# SPC1169 register map
File version: 2022071043481212
CPU: cm4 r1p0, little endian, no MPU, FPU, 4 interrupt priority bits
Registers are 32-bit, read-write, reset 0x0 unless marked. A register's access mark holds for its fields unless they carry their own. Offsets are from the block's base; [hi:lo] are bit positions; {n}, {i} and the like mark numbered series; 'fields as' and 'values as' point back to an identical list.

## GPIO
Base 0x40001200
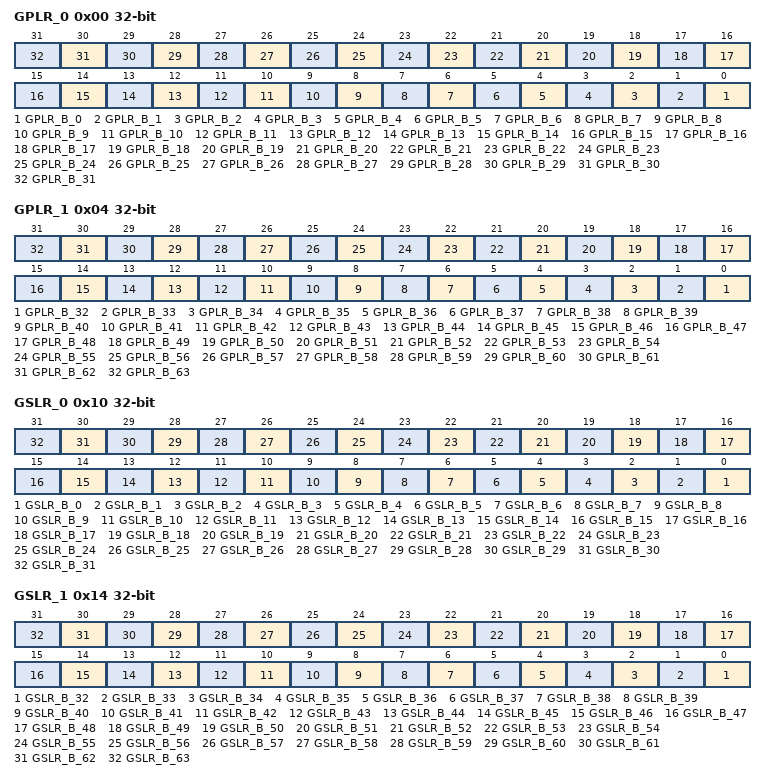
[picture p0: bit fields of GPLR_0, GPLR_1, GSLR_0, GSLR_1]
0x00 GPLR_0 — GPIO Pin Level Register [0]
  [n] GPLR_B_{n} (n=0..31)
0x04 GPLR_1 — GPIO Pin Level Register [1]
  [n-32] GPLR_B_{n} (n=32..63)
0x10 GSLR_0 — GPIO Pin Output Set Register [0]
  [n] GSLR_B_{n} (n=0..31)
0x14 GSLR_1 — GPIO Pin Output Set Register [1]
  [n-32] GSLR_B_{n} (n=32..63)
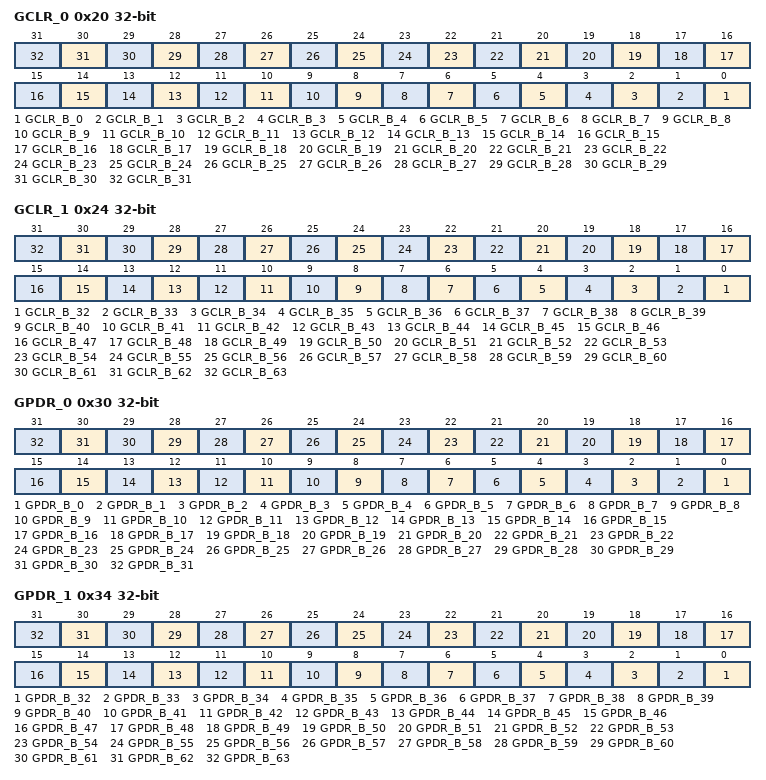
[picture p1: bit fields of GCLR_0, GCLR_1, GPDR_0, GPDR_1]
0x20 GCLR_0 — GPIO Pin Output Clear Register [0]
  [n] GCLR_B_{n} (n=0..31)
0x24 GCLR_1 — GPIO Pin Output Clear Register [1]
  [n-32] GCLR_B_{n} (n=32..63)
0x30 GPDR_0 — GPIO Pin Direction Register [0]
  [n] GPDR_B_{n} (n=0..31)
0x34 GPDR_1 — GPIO Pin Direction Register [1]
  [n-32] GPDR_B_{n} (n=32..63)
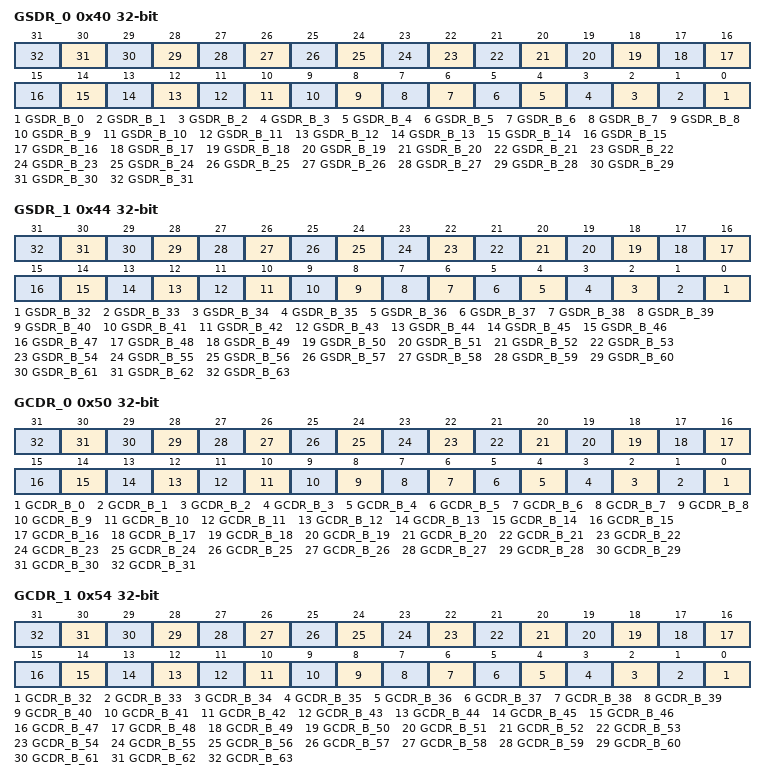
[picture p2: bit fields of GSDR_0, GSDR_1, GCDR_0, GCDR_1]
0x40 GSDR_0 — GPIO Pin Bitwise Set Direction Register [0]
  [n] GSDR_B_{n} (n=0..31)
0x44 GSDR_1 — GPIO Pin Bitwise Set Direction Register [1]
  [n-32] GSDR_B_{n} (n=32..63)
0x50 GCDR_0 — GPIO Pin Bitwise Clear Direction Register [0]
  [n] GCDR_B_{n} (n=0..31)
0x54 GCDR_1 — GPIO Pin Bitwise Clear Direction Register [1]
  [n-32] GCDR_B_{n} (n=32..63)
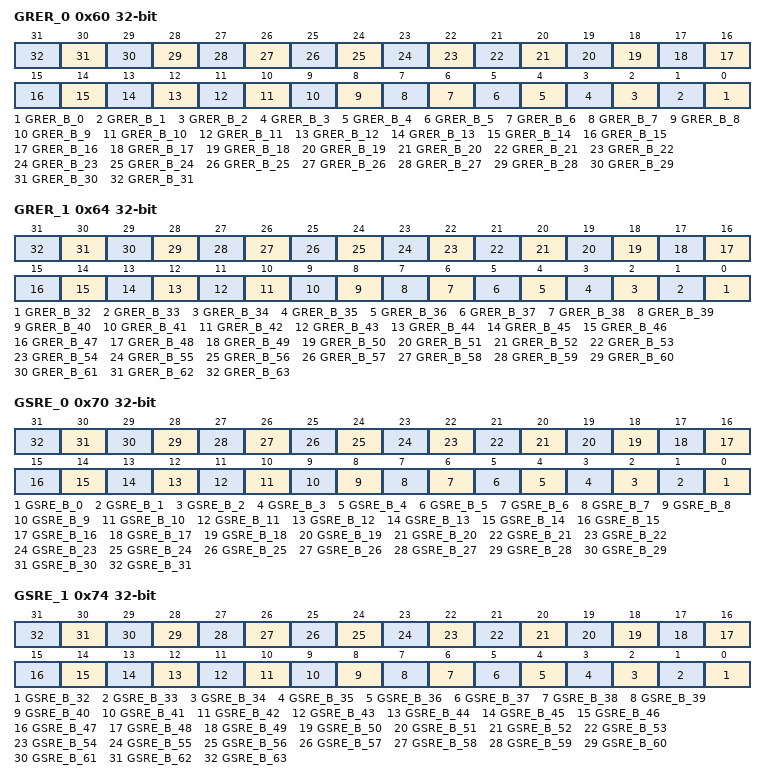
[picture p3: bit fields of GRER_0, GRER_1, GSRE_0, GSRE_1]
0x60 GRER_0 — GPIO Pin Rising Edge Detect Enable Register [0]
  [n] GRER_B_{n} (n=0..31)
0x64 GRER_1 — GPIO Pin Rising Edge Detect Enable Register [1]
  [n-32] GRER_B_{n} (n=32..63)
0x70 GSRE_0 — GPIO Pin Bitwise Set Rising Edge Detect Enable Register [0]
  [n] GSRE_B_{n} (n=0..31)
0x74 GSRE_1 — GPIO Pin Bitwise Set Rising Edge Detect Enable Register [1]
  [n-32] GSRE_B_{n} (n=32..63)
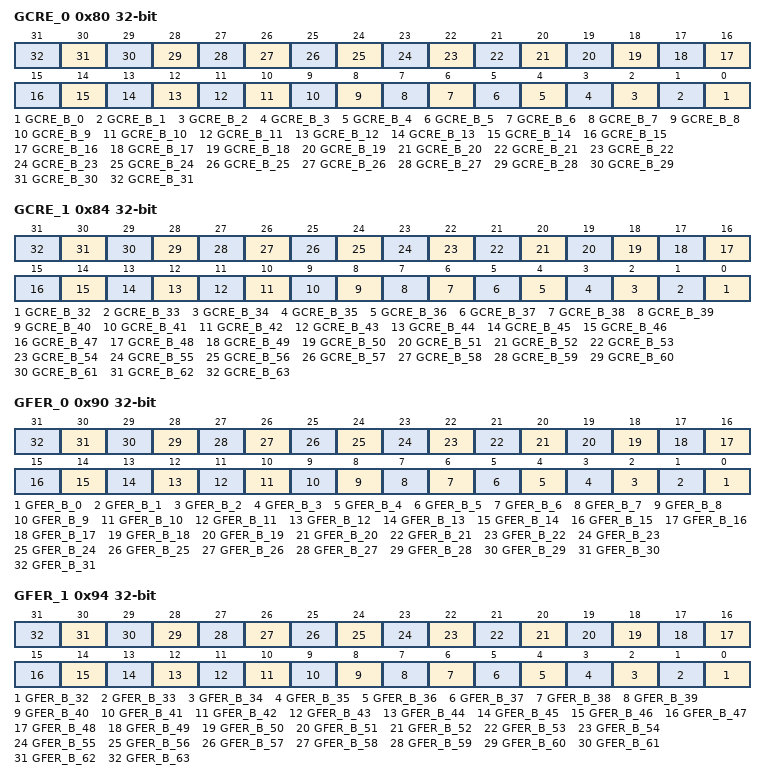
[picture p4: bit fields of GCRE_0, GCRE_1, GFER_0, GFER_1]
0x80 GCRE_0 — GPIO Pin Bitwise Clear Rising Edge Detect Enable Register [0]
  [n] GCRE_B_{n} (n=0..31)
0x84 GCRE_1 — GPIO Pin Bitwise Clear Rising Edge Detect Enable Register [1]
  [n-32] GCRE_B_{n} (n=32..63)
0x90 GFER_0 — GPIO Pin Falling Edge Detect Enable Register [0]
  [n] GFER_B_{n} (n=0..31)
0x94 GFER_1 — GPIO Pin Falling Edge Detect Enable Register [1]
  [n-32] GFER_B_{n} (n=32..63)
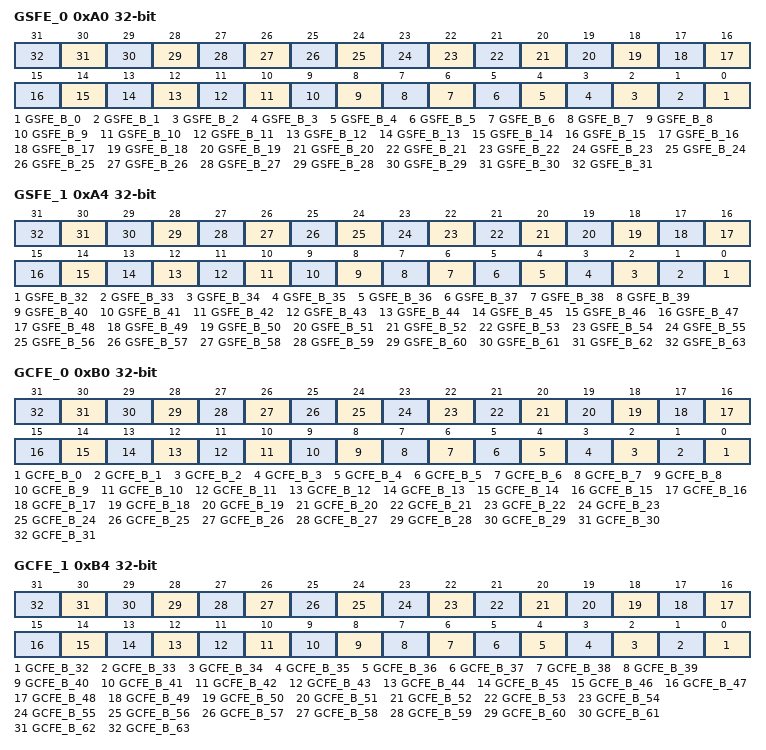
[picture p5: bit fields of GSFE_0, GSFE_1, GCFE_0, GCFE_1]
0xA0 GSFE_0 — GPIO Pin Bitwise Set Falling Edge Detect Enable Register [0]
  [n] GSFE_B_{n} (n=0..31)
0xA4 GSFE_1 — GPIO Pin Bitwise Set Falling Edge Detect Enable Register [1]
  [n-32] GSFE_B_{n} (n=32..63)
0xB0 GCFE_0 — GPIO Pin Bitwise Clear Falling Edge Detect Enable Register [0]
  [n] GCFE_B_{n} (n=0..31)
0xB4 GCFE_1 — GPIO Pin Bitwise Clear Falling Edge Detect Enable Register [1]
  [n-32] GCFE_B_{n} (n=32..63)
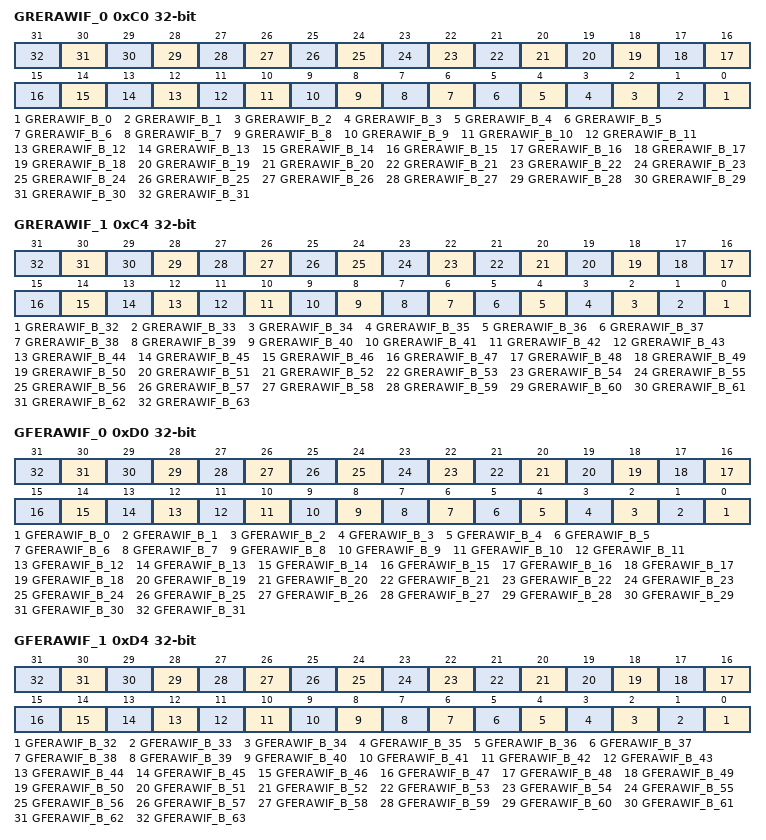
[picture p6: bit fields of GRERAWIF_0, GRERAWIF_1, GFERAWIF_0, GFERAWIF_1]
0xC0 GRERAWIF_0 ro — GPIO Pin Rising Edge Detect Interrupt Raw Flag Register [0]
  [n] GRERAWIF_B_{n} (n=0..31)
0xC4 GRERAWIF_1 ro — GPIO Pin Rising Edge Detect Interrupt Raw Flag Register [1]
  [n-32] GRERAWIF_B_{n} (n=32..63)
0xD0 GFERAWIF_0 ro — GPIO Pin Falling Edge Detect Interrupt Raw Flag Register [0]
  [n] GFERAWIF_B_{n} (n=0..31)
0xD4 GFERAWIF_1 ro — GPIO Pin Falling Edge Detect Interrupt Raw Flag Register [1]
  [n-32] GFERAWIF_B_{n} (n=32..63)
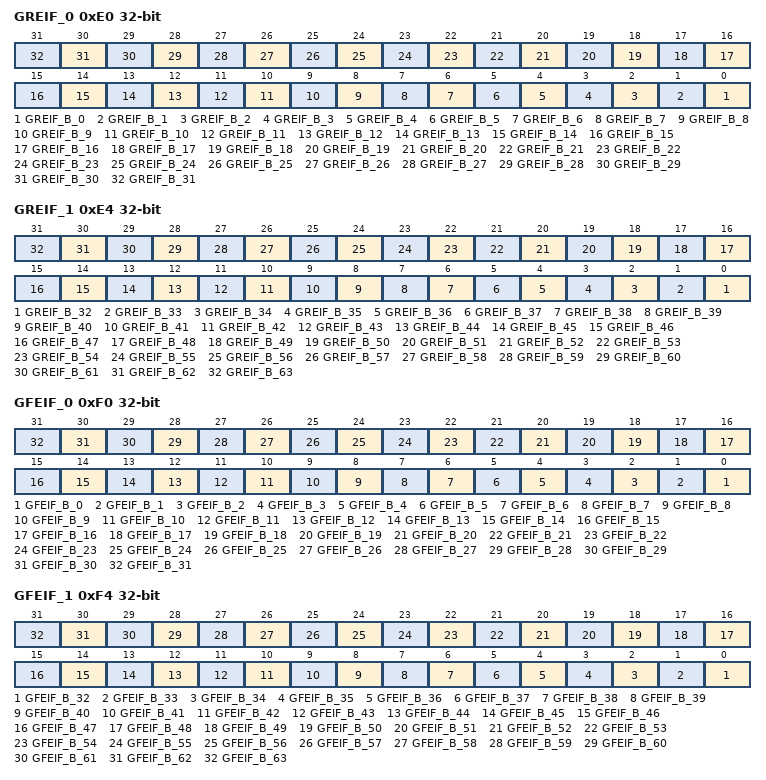
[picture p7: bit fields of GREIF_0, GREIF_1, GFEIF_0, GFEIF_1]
0xE0 GREIF_0 ro — GPIO Pin Rising Edge Triggered Interrupt Flag Register [0]
  [n] GREIF_B_{n} (n=0..31)
0xE4 GREIF_1 ro — GPIO Pin Rising Edge Triggered Interrupt Flag Register [1]
  [n-32] GREIF_B_{n} (n=32..63)
0xF0 GFEIF_0 ro — GPIO Pin Falling Edge triggered Interrupt Flag Register [0]
  [n] GFEIF_B_{n} (n=0..31)
0xF4 GFEIF_1 ro — GPIO Pin Falling Edge triggered Interrupt Flag Register [1]
  [n-32] GFEIF_B_{n} (n=32..63)
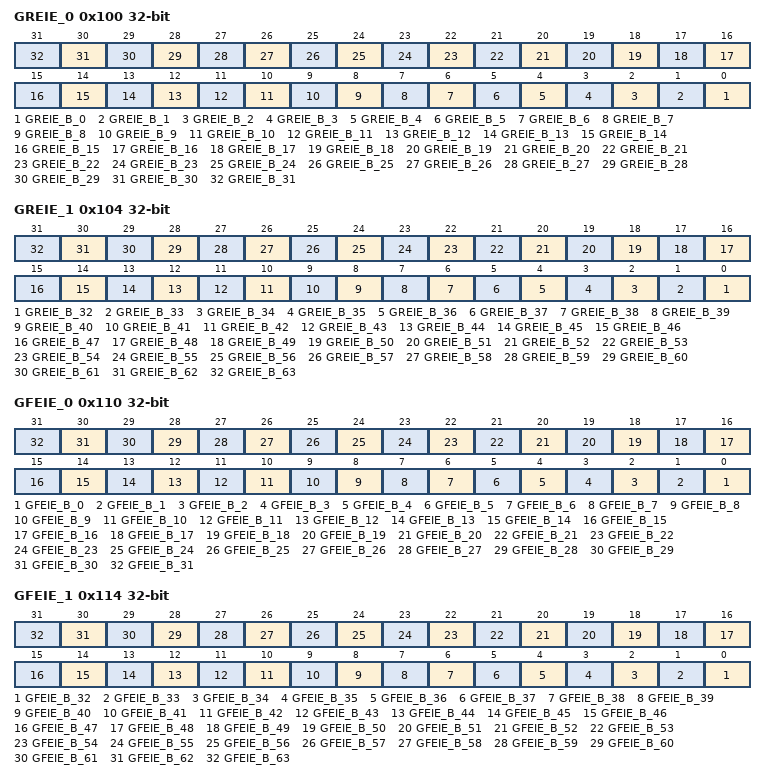
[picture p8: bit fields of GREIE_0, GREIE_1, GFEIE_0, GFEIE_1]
0x100 GREIE_0 — GPIO Pin Rising Edge Triggered Interrupt Enable Register [0]
  [n] GREIE_B_{n} (n=0..31)
0x104 GREIE_1 — GPIO Pin Rising Edge Triggered Interrupt Enable Register [1]
  [n-32] GREIE_B_{n} (n=32..63)
0x110 GFEIE_0 — GPIO Pin Falling Edge Triggered Interrupt Enable Register [0]
  [n] GFEIE_B_{n} (n=0..31)
0x114 GFEIE_1 — GPIO Pin Falling Edge Triggered Interrupt Enable Register [1]
  [n-32] GFEIE_B_{n} (n=32..63)
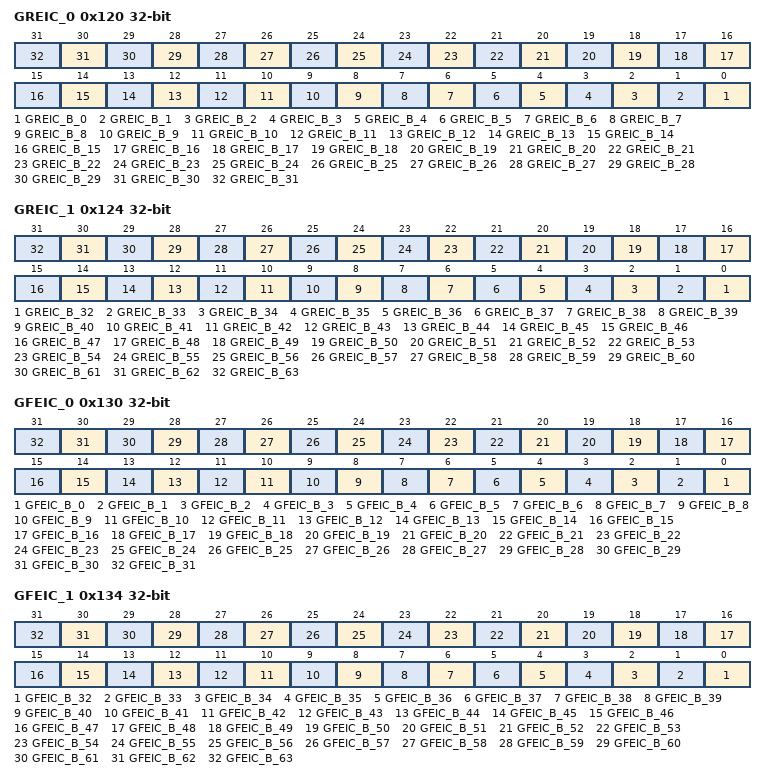
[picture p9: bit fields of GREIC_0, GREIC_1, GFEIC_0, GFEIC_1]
0x120 GREIC_0 — GPIO Pin Rising Edge Triggered Interrupt Clear Register [0]
  [n] GREIC_B_{n} (n=0..31)
0x124 GREIC_1 — GPIO Pin Rising Edge Triggered Interrupt Clear Register [1]
  [n-32] GREIC_B_{n} (n=32..63)
0x130 GFEIC_0 — GPIO Pin Falling Edge Triggered Interrupt Clear Register [0]
  [n] GFEIC_B_{n} (n=0..31)
0x134 GFEIC_1 — GPIO Pin Falling Edge Triggered Interrupt Clear Register [1]
  [n-32] GFEIC_B_{n} (n=32..63)
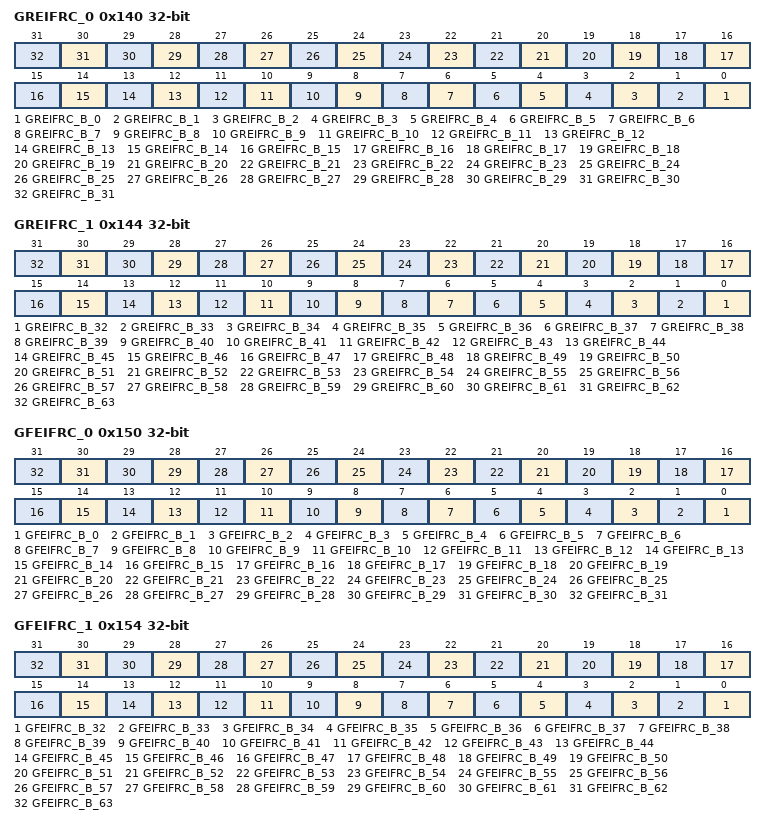
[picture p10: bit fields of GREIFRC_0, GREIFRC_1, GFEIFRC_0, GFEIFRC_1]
0x140 GREIFRC_0 — GPIO Pin Rising Edge Event Force Register [0]
  [n] GREIFRC_B_{n} (n=0..31)
0x144 GREIFRC_1 — GPIO Pin Rising Edge Event Force Register [1]
  [n-32] GREIFRC_B_{n} (n=32..63)
0x150 GFEIFRC_0 — GPIO Pin Falling Edge Event Force Register [0]
  [n] GFEIFRC_B_{n} (n=0..31)
0x154 GFEIFRC_1 — GPIO Pin Falling Edge Event Force Register [1]
  [n-32] GFEIFRC_B_{n} (n=32..63)
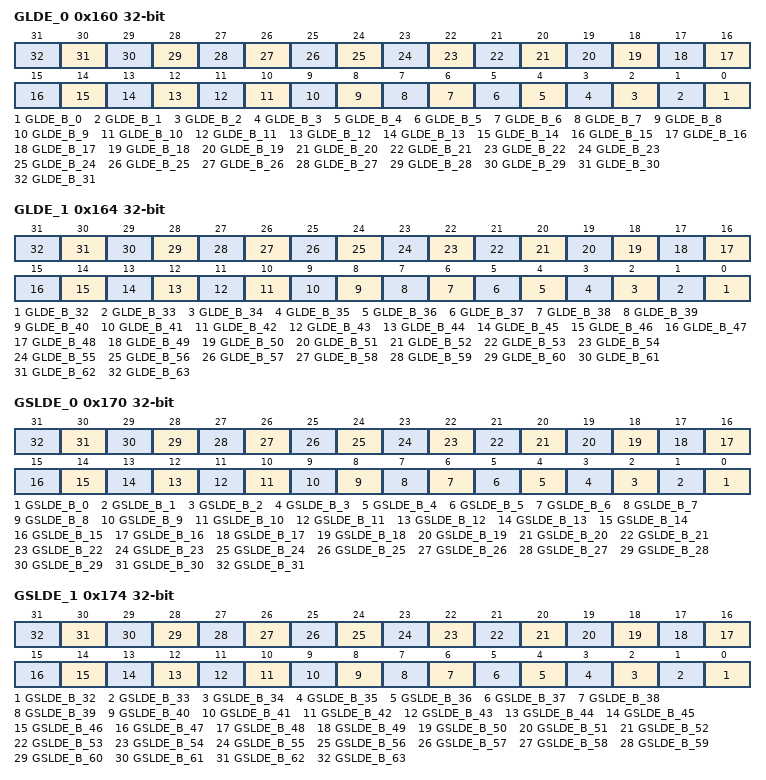
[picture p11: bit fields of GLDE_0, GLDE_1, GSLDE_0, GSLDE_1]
0x160 GLDE_0 — GPIO Pin Level Detect Enable Register [0]
  [n] GLDE_B_{n} (n=0..31)
0x164 GLDE_1 — GPIO Pin Level Detect Enable Register [1]
  [n-32] GLDE_B_{n} (n=32..63)
0x170 GSLDE_0 — GPIO Pin Bitwise Set Level Detect Enable Register [0]
  [n] GSLDE_B_{n} (n=0..31)
0x174 GSLDE_1 — GPIO Pin Bitwise Set Level Detect Enable Register [1]
  [n-32] GSLDE_B_{n} (n=32..63)
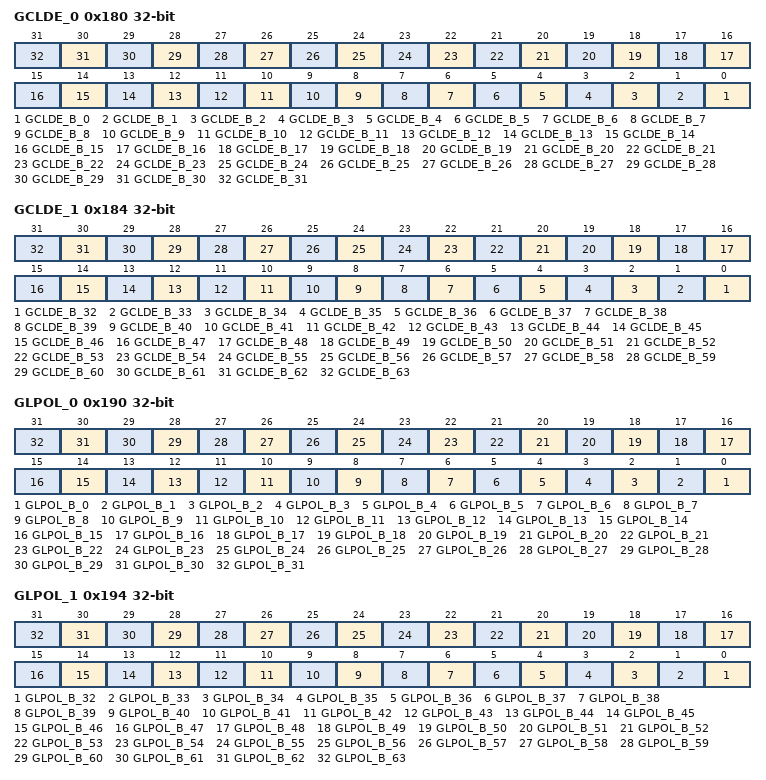
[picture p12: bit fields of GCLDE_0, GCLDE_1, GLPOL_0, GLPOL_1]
0x180 GCLDE_0 — GPIO Pin Bitwise Clear Level Detect Enable Register [0]
  [n] GCLDE_B_{n} (n=0..31)
0x184 GCLDE_1 — GPIO Pin Bitwise Clear Level Detect Enable Register [1]
  [n-32] GCLDE_B_{n} (n=32..63)
0x190 GLPOL_0 — GPIO Pin Level Detect Polarity Register [0]
  [n] GLPOL_B_{n} (n=0..31)
0x194 GLPOL_1 — GPIO Pin Level Detect Polarity Register [1]
  [n-32] GLPOL_B_{n} (n=32..63)
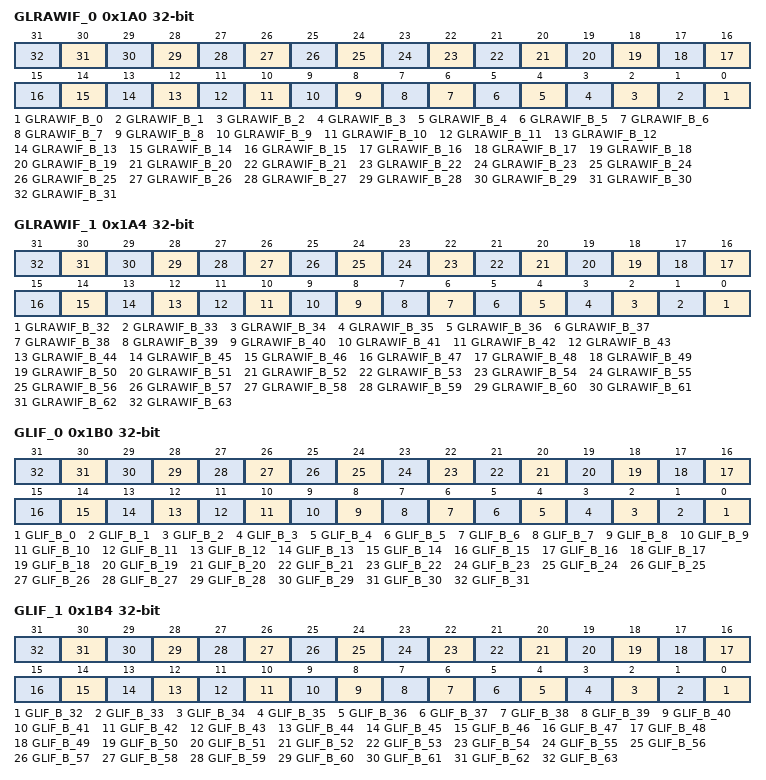
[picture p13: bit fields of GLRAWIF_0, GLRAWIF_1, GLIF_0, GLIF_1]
0x1A0 GLRAWIF_0 ro — GPIO Pin Level Detect Interrupt Raw Flag Register [0]
  [n] GLRAWIF_B_{n} (n=0..31)
0x1A4 GLRAWIF_1 ro — GPIO Pin Level Detect Interrupt Raw Flag Register [1]
  [n-32] GLRAWIF_B_{n} (n=32..63)
0x1B0 GLIF_0 ro — GPIO Pin Level-Triggered Interrupt Flag Register [0]
  [n] GLIF_B_{n} (n=0..31)
0x1B4 GLIF_1 ro — GPIO Pin Level-Triggered Interrupt Flag Register [1]
  [n-32] GLIF_B_{n} (n=32..63)
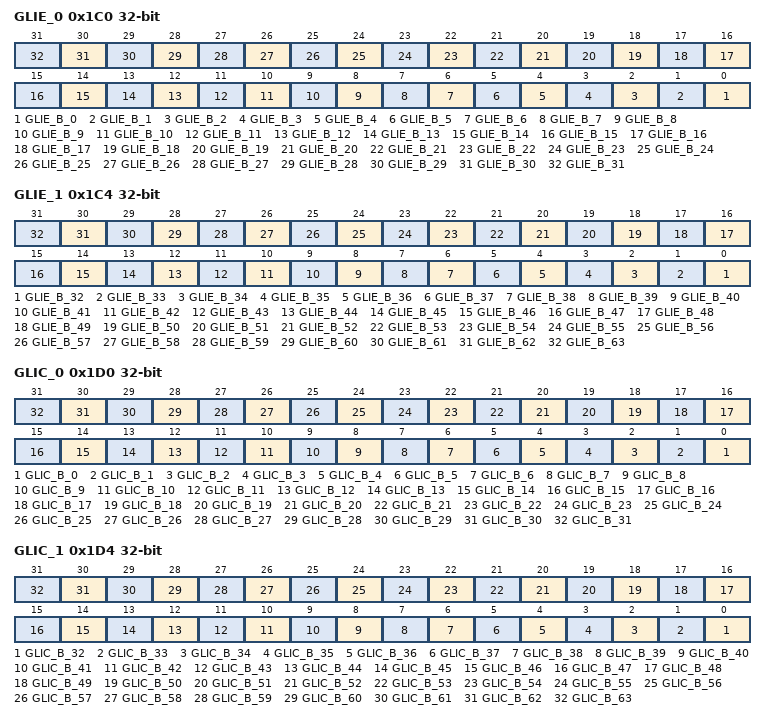
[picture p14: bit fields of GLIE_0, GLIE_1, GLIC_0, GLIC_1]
0x1C0 GLIE_0 — GPIO Pin Level-Triggered Interrupt Enable Register [0]
  [n] GLIE_B_{n} (n=0..31)
0x1C4 GLIE_1 — GPIO Pin Level-Triggered Interrupt Enable Register [1]
  [n-32] GLIE_B_{n} (n=32..63)
0x1D0 GLIC_0 — GPIO Pin Level-Triggered Interrupt Clear Register [0]
  [n] GLIC_B_{n} (n=0..31)
0x1D4 GLIC_1 — GPIO Pin Level-Triggered Interrupt Clear Register [1]
  [n-32] GLIC_B_{n} (n=32..63)
0x1E0 GLIFRC_0 — GPIO Pin Level-Triggered Event Force Register [0]
  [n] GLIFRC_B_{n} (n=0..31)
0x1E4 GLIFRC_1 — GPIO Pin Level-Triggered Event Force Register [1]
  [n-32] GLIFRC_B_{n} (n=32..63)
0x1F0 GGRAWIF ro — GPIO Global Interrupt Raw Flag Register
  [3] FEDGE — Global GPIO falling edge event flag. This bit is the logic OR of GFERAWIF bits
    0=NOT_OCCUR (No falling edge was detected on GPIO); 1=OCCUR (Falling edge was detected on GPIO)
  [2] REDGE — Global GPIO rising edge event flag. This bit is the logic OR of GRERAWIF bits
    0=NOT_OCCUR (No rising edge was detected on GPIO); 1=OCCUR (Rising edge was detected on GPIO)
  [1] EDGE — Global GPIO edge event flag. This bit is the logic OR of GRERAWIF and GFERAWIF bits
    0=NOT_OCCUR (No edge was detected on GPIO); 1=OCCUR (Edge was detected on GPIO)
  [0] LEVEL — Global GPIO level event flag. This bit is the logic OR of GLRAWIF bits
    0=NOT_OCCUR (Specified level was not detected on GPIO); 1=OCCUR (Specified level was detected on GPIO)
0x1F4 GGIF ro — GPIO Global Interrupt Flag Register
  [1] EDGE — Global GPIO edge-triggered interrupt flag
    0=NOT_OCCUR (Edge-triggered interrupt does not occur); 1=OCCUR (Edge-triggered interrupt occurred and issued to the CPU. Further interrupt will not be generated until this bit is cleared.)
  [0] LEVEL — Global GPIO level-triggered interrupt flag
    0=NOT_OCCUR (Level-triggered interrupt does not occur); 1=OCCUR (Level-triggered interrupt occurred and issued to the CPU. Further interrupt will not be generated until this bit is cleared.)
0x1F8 GGIC — GPIO Global Interrupt Clear Register
  [1] EDGE — Global GPIO edge-triggered interrupt clear
    0=NO_EFFECT (Write a 0 has no effet and always reads back 0); 1=CLEAR (Write a 1 clears the flag. This bit is self-cleared.)
  [0] LEVEL — Global GPIO level-triggered interrupt clear
    values as EDGE
0x1FC GPIOREGKEY reset 0x1ACCE551 — GPIO Register Write-Allow Key Register
  [31:0] KEY — Write 0x1ACCE551 to unlock protected GPIO registers
